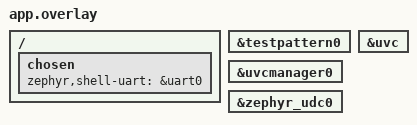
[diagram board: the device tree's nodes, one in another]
/*
 * Copyright (c) 2024 tinyVision.ai Inc.
 *
 * SPDX-License-Identifier: Apache-2.0
 */

/ {
	chosen {
		zephyr,shell-uart = &uart0;
	};
};

&testpattern0 {
	status = "okay";
};

&uvcmanager0 {
	status = "okay";
};

&uvc {
	status = "okay";
};

&zephyr_udc0 {
	status = "okay";
};
